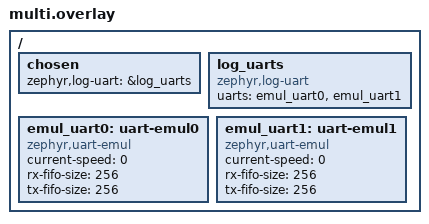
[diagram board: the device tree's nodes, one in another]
/*
 * Copyright (c) 2023 Meta
 *
 * SPDX-License-Identifier: Apache-2.0
 */

/ {
	chosen {
		zephyr,log-uart = &log_uarts;
	};

	log_uarts: log_uarts {
		compatible = "zephyr,log-uart";
		uarts = <&emul_uart0 &emul_uart1>;
	};

	emul_uart0: uart-emul0 {
		compatible = "zephyr,uart-emul";
		status = "okay";
		current-speed = <0>;
		rx-fifo-size = <256>;
		tx-fifo-size = <256>;
	};

	emul_uart1: uart-emul1 {
		compatible = "zephyr,uart-emul";
		status = "okay";
		current-speed = <0>;
		rx-fifo-size = <256>;
		tx-fifo-size = <256>;
	};
};
